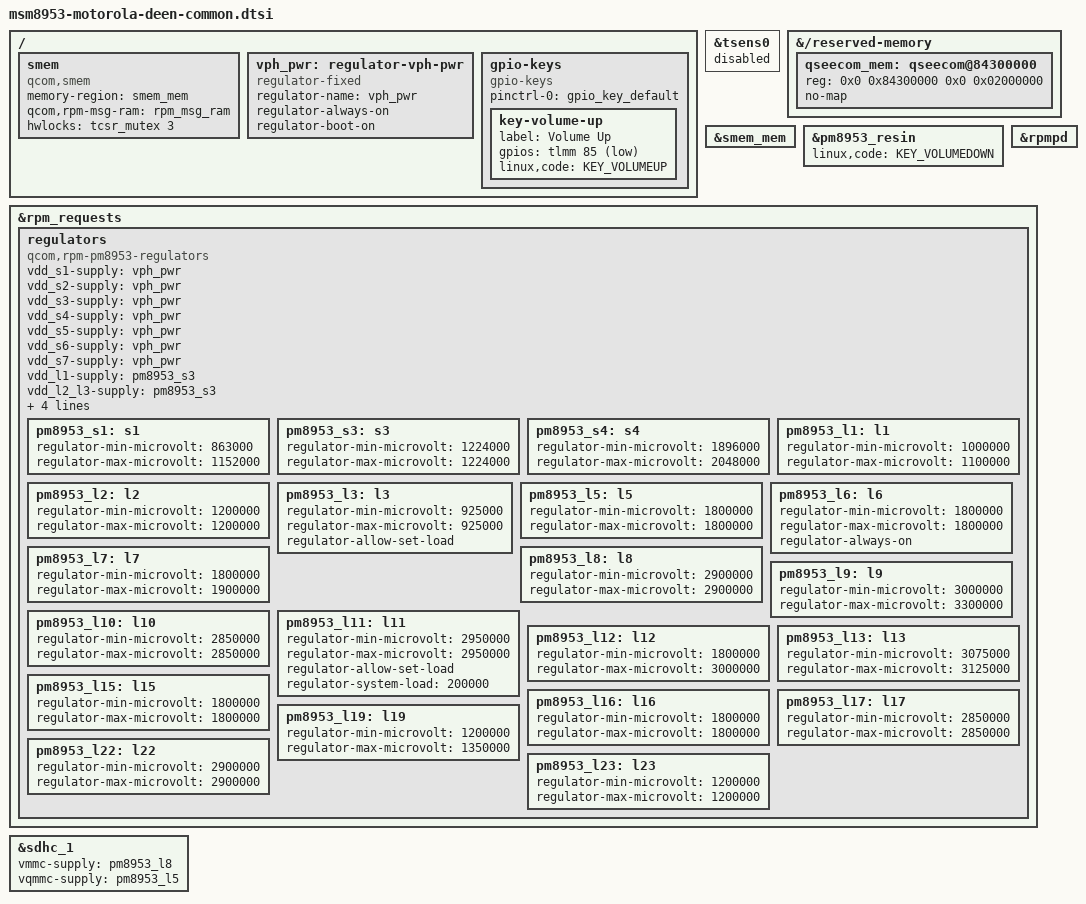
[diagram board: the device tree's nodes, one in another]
// SPDX-License-Identifier: (GPL-2.0+ OR BSD-3-Clause)
/*
 * Minimal Motorola One Deen board foundation for ACK 5.15.
 *
 * The MSM8953 and PM8953 SoC descriptions are imported unchanged from
 * torvalds/linux v6.1. Regulator values and the eMMC supply mapping are
 * adapted from the upstream Motorola Deen DTS added in commit
 * b62af30ebdb4ae4ec6230c5e39eea97f65b9f5ea.
 *
 * This file is intentionally limited to board identity-independent basics:
 * volume keys, PMIC regulators and the primary eMMC controller.
 * It is not a complete or flashable device tree.
 */

#include <dt-bindings/gpio/gpio.h>
#include <dt-bindings/input/linux-event-codes.h>

#include "msm8953.dtsi"
#include "pm8953.dtsi"

/*
 * DEEN THERMAL HOLD: The verified stock C100/C200 FDT uses 15 TSENS_TYPE3
 * sensors with hardware IDs 1..15. The inherited msm8953.dtsi instead
 * describes 16 sensors using the unverified generic v2 register map.
 *
 * Quarantine this Deen-only controller until its type-3 register mapping,
 * calibration, IRQs and thermal protection have been reviewed. This is
 * NOT a safe boot configuration: a correct thermal driver is still required
 * before producing a flashable image.
 */
&tsens0 {
	status = "disabled";
};

/*
 * Motorola Deen memory layout:
 * - Move the inherited MSM8953 QSEE region from 0x85b00000/8 MiB
 *   to the Deen-specific 0x84300000/32 MiB region used by mainline Deen.
 * - Drop the continuous splash reservation because the initial Deen
 *   display path is not enabled in this bring-up.
 *
 * These two inherited reservations are anonymous in the v6.1 MSM8953 DTSI,
 * so delete them by their reserved-memory child names.
 */
&{/reserved-memory} {
	/delete-node/ memory@85b00000;
	/delete-node/ memory@90001000;

	qseecom_mem: qseecom@84300000 {
		reg = <0x0 0x84300000 0x0 0x02000000>;
		no-map;
	};
};


/*
 * Keep the SMEM reservation separate from the qcom,smem platform device.
 * The ACK 5.15 driver maps the region through the device's memory-region
 * phandle; putting qcom,smem on the reserved-memory child makes the driver
 * probe the reservation node itself without that required phandle.
 */
&smem_mem {
	/delete-property/ compatible;
	/delete-property/ qcom,rpm-msg-ram;
	/delete-property/ hwlocks;
};

/ {
	smem {
		compatible = "qcom,smem";
		memory-region = <&smem_mem>;
		qcom,rpm-msg-ram = <&rpm_msg_ram>;
		hwlocks = <&tcsr_mutex 3>;
	};
};

/ {
	vph_pwr: regulator-vph-pwr {
		compatible = "regulator-fixed";
		regulator-name = "vph_pwr";
		regulator-always-on;
		regulator-boot-on;
	};

	gpio-keys {
		compatible = "gpio-keys";

		pinctrl-0 = <&gpio_key_default>;
		pinctrl-names = "default";

		key-volume-up {
			label = "Volume Up";
			gpios = <&tlmm 85 GPIO_ACTIVE_LOW>;
			linux,code = <KEY_VOLUMEUP>;
		};
	};
};

&pm8953_resin {
	linux,code = <KEY_VOLUMEDOWN>;
	status = "okay";
};

/*
 * ACK 5.15 rpmpd.c obtains its RPM handle from the parent SMD device;
 * it does not request a clock from this node. Drop the inherited, unused
 * XO clock reference for Deen only and leave msm8953.dtsi unchanged.
 */
&rpmpd {
	/delete-property/ clocks;
	/delete-property/ clock-names;
};

&rpm_requests {
	regulators {
		compatible = "qcom,rpm-pm8953-regulators";

		vdd_s1-supply = <&vph_pwr>;
		vdd_s2-supply = <&vph_pwr>;
		vdd_s3-supply = <&vph_pwr>;
		vdd_s4-supply = <&vph_pwr>;
		vdd_s5-supply = <&vph_pwr>;
		vdd_s6-supply = <&vph_pwr>;
		vdd_s7-supply = <&vph_pwr>;
		vdd_l1-supply = <&pm8953_s3>;
		vdd_l2_l3-supply = <&pm8953_s3>;
		vdd_l4_l5_l6_l7_l16_l19-supply = <&pm8953_s4>;
		vdd_l8_l11_l12_l13_l14_l15-supply = <&vph_pwr>;
		vdd_l9_l10_l17_l18_l22-supply = <&vph_pwr>;
		vdd_l23-supply = <&pm8953_s3>;

		pm8953_s1: s1 {
			regulator-min-microvolt = <863000>;
			regulator-max-microvolt = <1152000>;
		};

		pm8953_s3: s3 {
			regulator-min-microvolt = <1224000>;
			regulator-max-microvolt = <1224000>;
		};

		pm8953_s4: s4 {
			regulator-min-microvolt = <1896000>;
			regulator-max-microvolt = <2048000>;
		};

		pm8953_l1: l1 {
			regulator-min-microvolt = <1000000>;
			regulator-max-microvolt = <1100000>;
		};

		pm8953_l2: l2 {
			regulator-min-microvolt = <1200000>;
			regulator-max-microvolt = <1200000>;
		};

		pm8953_l3: l3 {
			regulator-min-microvolt = <925000>;
			regulator-max-microvolt = <925000>;
			regulator-allow-set-load;
		};

		pm8953_l5: l5 {
			regulator-min-microvolt = <1800000>;
			regulator-max-microvolt = <1800000>;
		};

		pm8953_l6: l6 {
			regulator-min-microvolt = <1800000>;
			regulator-max-microvolt = <1800000>;
			regulator-always-on;
		};

		pm8953_l7: l7 {
			regulator-min-microvolt = <1800000>;
			regulator-max-microvolt = <1900000>;
		};

		pm8953_l8: l8 {
			regulator-min-microvolt = <2900000>;
			regulator-max-microvolt = <2900000>;
		};

		pm8953_l9: l9 {
			regulator-min-microvolt = <3000000>;
			regulator-max-microvolt = <3300000>;
		};

		pm8953_l10: l10 {
			regulator-min-microvolt = <2850000>;
			regulator-max-microvolt = <2850000>;
		};

		pm8953_l11: l11 {
			regulator-min-microvolt = <2950000>;
			regulator-max-microvolt = <2950000>;
			regulator-allow-set-load;
			regulator-system-load = <200000>;
		};

		pm8953_l12: l12 {
			regulator-min-microvolt = <1800000>;
			regulator-max-microvolt = <3000000>;
		};

		pm8953_l13: l13 {
			regulator-min-microvolt = <3075000>;
			regulator-max-microvolt = <3125000>;
		};

		pm8953_l15: l15 {
			regulator-min-microvolt = <1800000>;
			regulator-max-microvolt = <1800000>;
		};

		pm8953_l16: l16 {
			regulator-min-microvolt = <1800000>;
			regulator-max-microvolt = <1800000>;
		};

		pm8953_l17: l17 {
			regulator-min-microvolt = <2850000>;
			regulator-max-microvolt = <2850000>;
		};

		pm8953_l19: l19 {
			regulator-min-microvolt = <1200000>;
			regulator-max-microvolt = <1350000>;
		};

		pm8953_l22: l22 {
			regulator-min-microvolt = <2900000>;
			regulator-max-microvolt = <2900000>;
		};

		pm8953_l23: l23 {
			regulator-min-microvolt = <1200000>;
			regulator-max-microvolt = <1200000>;
		};
	};
};

/* Primary non-removable eMMC: keep peripheral enablement to boot storage. */
&sdhc_1 {
	vmmc-supply = <&pm8953_l8>;
	vqmmc-supply = <&pm8953_l5>;
	status = "okay";
};
